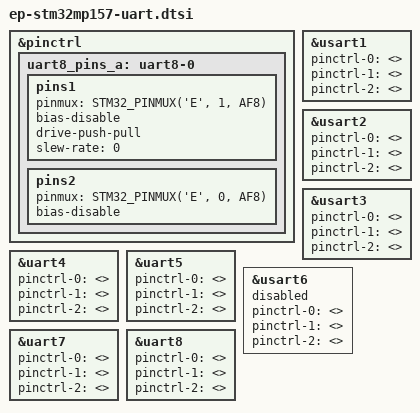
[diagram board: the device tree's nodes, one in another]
// SPDX-License-Identifier: (GPL-2.0+ OR BSD-3-Clause)
/*
 * Copyright (C) STMicroelectronics 2017 - All Rights Reserved
 * Author: Ludovic Barre <ludovic.barre@st.com> for STMicroelectronics.
 */
#include <dt-bindings/pinctrl/stm32-pinfunc.h>



&pinctrl {
	uart8_pins_a: uart8-0 {
		pins1 {
			pinmux = <STM32_PINMUX('E', 1, AF8)>; /* UART8_TX */
			bias-disable;
			drive-push-pull;
			slew-rate = <0>;
		};
		pins2 {
			pinmux = <STM32_PINMUX('E', 0, AF8)>; /* UART8_RX */
			bias-disable;
		};
	};
};

&usart1 {
	pinctrl-names = "default";
	pinctrl-0 = <>;
	pinctrl-1 = <>;
	pinctrl-2 = <>;
	status = "okay";
};

&usart2 {
	pinctrl-names = "default";
	pinctrl-0 = <>;
	pinctrl-1 = <>;
	pinctrl-2 = <>;
	status = "okay";
};

&usart3 {
	pinctrl-names = "default";
	pinctrl-0 = <>;
	pinctrl-1 = <>;
	pinctrl-2 = <>;
	status = "okay";
};

&uart4 {
	pinctrl-names = "default";
	pinctrl-0 = <>;
	pinctrl-1 = <>;
	pinctrl-2 = <>;
	status = "okay";
};

&uart5 {
	pinctrl-names = "default";
	pinctrl-0 = <>;
	pinctrl-1 = <>;
	pinctrl-2 = <>;
	status = "okay";
};

&usart6 {
	pinctrl-names = "default";
	pinctrl-0 = <>;
	pinctrl-1 = <>;
	pinctrl-2 = <>;
	status = "disabled";
};


&uart7 {
	pinctrl-names = "default";
	pinctrl-0 = <>;
	pinctrl-1 = <>;
	pinctrl-2 = <>;
	status = "okay";
};

&uart8 {
	pinctrl-names = "default";
	pinctrl-0 = <>;
	pinctrl-1 = <>;
	pinctrl-2 = <>;
	status = "okay";
};
